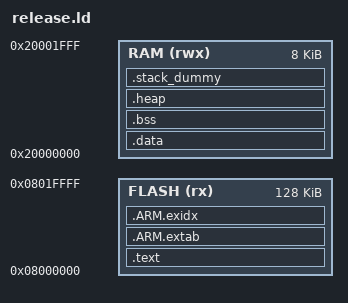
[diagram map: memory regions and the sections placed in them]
/*******************************************************************************

 ******************************************************************************/

/* Setup memory origins and sizes. */
MEMORY
{
	FLASH	(rx)  : ORIGIN = 0x08000000, LENGTH = 128K
  	RAM 	(rwx) : ORIGIN = 0x20000000, LENGTH = 8K
}

/* Entry point to begin program. */
ENTRY(reset_handler)

/* Code and data sections. */
SECTIONS
{
	.text : ALIGN(4)
    {
        FILL(0xff)
        __vectors_start__ = ABSOLUTE(.) ;
        KEEP(*(.isr_vector))
        
        /* Global Section Table. */
        . = ALIGN(4) ;
        __section_table_start = .;
        __data_section_table = .;
        LONG(LOADADDR(.data));
        LONG(    ADDR(.data)) ;
        LONG(  SIZEOF(.data));
        __data_section_table_end = .;
        __bss_section_table = .;
        LONG(    ADDR(.bss));
        LONG(  SIZEOF(.bss));
        __bss_section_table_end = .;
        __section_table_end = . ;
        /* End of Global Section Table. */
        
        *(.after_vectors*)
        
    } > FLASH

	.ARM.extab : 
	{
		*(.ARM.extab* .gnu.linkonce.armextab.*)
	} > FLASH

	__exidx_start = .;
	.ARM.exidx :
	{
		*(.ARM.exidx* .gnu.linkonce.armexidx.*)
	} > FLASH
	__exidx_end = .;

	__etext = .;
		
	.data : AT (__etext)
	{
		__data_start__ = .;
		*(vtable)
		*(.data*)

		. = ALIGN(4);
		/* preinit data */
		PROVIDE_HIDDEN (__preinit_array_start = .);
		KEEP(*(.preinit_array))
		PROVIDE_HIDDEN (__preinit_array_end = .);

		. = ALIGN(4);
		/* init data */
		PROVIDE_HIDDEN (__init_array_start = .);
		KEEP(*(SORT(.init_array.*)))
		KEEP(*(.init_array))
		PROVIDE_HIDDEN (__init_array_end = .);

		. = ALIGN(4);
		/* finit data */
		PROVIDE_HIDDEN (__fini_array_start = .);
		KEEP(*(SORT(.fini_array.*)))
		KEEP(*(.fini_array))
		PROVIDE_HIDDEN (__fini_array_end = .);

		. = ALIGN(4);
		/* All data end */
		__data_end__ = .;

	} > RAM

	.bss :
	{
		__bss_start__ = .;
		*(.bss*)
		*(COMMON)
		__bss_end__ = .;
	} > RAM
	
	.heap :
	{
		__end__ = .;
		end = __end__;
		*(.heap*)
		__HeapLimit = .;
	} > RAM

	/* .stack_dummy section doesn't contains any symbols. It is only
	   used for linker to calculate size of stack sections, and assign
	   values to stack symbols later. */
	.stack_dummy :
	{
		*(.stack*)
	} > RAM

	/* Set stack top to end of RAM, and stack limit move down by
	   size of stack_dummy section. */
	__StackTop = ORIGIN(RAM) + LENGTH(RAM);
	__StackLimit = __StackTop - SIZEOF(.stack_dummy);
	PROVIDE(_vStackTop = __StackTop);
	
	/* Check if data + heap + stack exceeds RAM limit. */
	ASSERT(__StackLimit >= __HeapLimit, "region RAM overflowed with stack")
}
